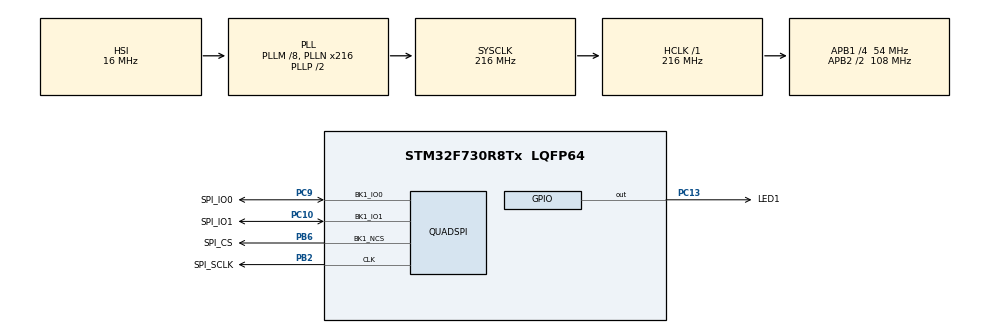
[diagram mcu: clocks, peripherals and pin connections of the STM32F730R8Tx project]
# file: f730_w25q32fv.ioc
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CORTEX_M7.ART_ACCLERATOR_ENABLE=0
CORTEX_M7.AccessPermission-Cortex_Memory_Protection_Unit_Region0_Settings=MPU_REGION_NO_ACCESS
CORTEX_M7.BaseAddress-Cortex_Memory_Protection_Unit_Region0_Settings=0x90000000
CORTEX_M7.CPU_DCache=Disabled
CORTEX_M7.CPU_ICache=Disabled
CORTEX_M7.DisableExec-Cortex_Memory_Protection_Unit_Region0_Settings=MPU_INSTRUCTION_ACCESS_ENABLE
CORTEX_M7.Enable-Cortex_Memory_Protection_Unit_Region0_Settings=MPU_REGION_ENABLE
CORTEX_M7.Enable-Cortex_Memory_Protection_Unit_Region10_Settings=__NULL
CORTEX_M7.Enable-Cortex_Memory_Protection_Unit_Region11_Settings=__NULL
CORTEX_M7.Enable-Cortex_Memory_Protection_Unit_Region12_Settings=__NULL
CORTEX_M7.Enable-Cortex_Memory_Protection_Unit_Region13_Settings=__NULL
CORTEX_M7.Enable-Cortex_Memory_Protection_Unit_Region14_Settings=__NULL
CORTEX_M7.Enable-Cortex_Memory_Protection_Unit_Region15_Settings=__NULL
CORTEX_M7.Enable-Cortex_Memory_Protection_Unit_Region1_Settings=__NULL
CORTEX_M7.Enable-Cortex_Memory_Protection_Unit_Region2_Settings=__NULL
CORTEX_M7.Enable-Cortex_Memory_Protection_Unit_Region3_Settings=__NULL
CORTEX_M7.Enable-Cortex_Memory_Protection_Unit_Region4_Settings=__NULL
CORTEX_M7.Enable-Cortex_Memory_Protection_Unit_Region5_Settings=__NULL
CORTEX_M7.Enable-Cortex_Memory_Protection_Unit_Region6_Settings=__NULL
CORTEX_M7.Enable-Cortex_Memory_Protection_Unit_Region7_Settings=__NULL
CORTEX_M7.Enable-Cortex_Memory_Protection_Unit_Region8_Settings=__NULL
CORTEX_M7.Enable-Cortex_Memory_Protection_Unit_Region9_Settings=__NULL
CORTEX_M7.FlashInterface=AXI_Enabled
CORTEX_M7.IsBufferable-Cortex_Memory_Protection_Unit_Region0_Settings=MPU_ACCESS_NOT_BUFFERABLE
CORTEX_M7.IsCacheable-Cortex_Memory_Protection_Unit_Region0_Settings=MPU_ACCESS_CACHEABLE
CORTEX_M7.IsShareable-Cortex_Memory_Protection_Unit_Region0_Settings=MPU_ACCESS_NOT_SHAREABLE
CORTEX_M7.MPU_Control=__NULL
CORTEX_M7.PREFETCH_ENABLE=0
CORTEX_M7.Size-Cortex_Memory_Protection_Unit_Region0_Settings=MPU_REGION_SIZE_4MB
CORTEX_M7.SubRegionDisable-Cortex_Memory_Protection_Unit_Region0_Settings=0x0
CORTEX_M7.TypeExtField-Cortex_Memory_Protection_Unit_Region0_Settings=MPU_TEX_LEVEL0
Mcu.Family=STM32F7
Mcu.Name=STM32F730R8Tx
Mcu.Package=LQFP64
NVIC.PriorityGroup=NVIC_PRIORITYGROUP_4
PA13.GPIO_Label=SWDIO
PA13.Mode=Serial_Wire
PA13.Signal=SYS_JTMS-SWDIO
PA14.GPIO_Label=SWCLK
PA14.Mode=Serial_Wire
PA14.Signal=SYS_JTCK-SWCLK
PB2.GPIO_Label=SPI_SCLK
PB2.Mode=Single Bank 1 2IOs
PB2.Signal=QUADSPI_CLK
PB6.GPIO_Label=SPI_CS
PB6.Mode=Single Bank 1 2IOs
PB6.Signal=QUADSPI_BK1_NCS
PC10.GPIO_Label=SPI_IO1
PC10.Mode=Single Bank 1 2IOs
PC10.Signal=QUADSPI_BK1_IO1
PC13.GPIO_Label=LED1
PC13.Signal=GPIO_Output
PC9.GPIO_Label=SPI_IO0
PC9.Mode=Single Bank 1 2IOs
PC9.Signal=QUADSPI_BK1_IO0
ProjectManager.HeapSize=0x200
ProjectManager.StackSize=0x400
ProjectManager.TargetToolchain=STM32CubeIDE
QUADSPI.ChipSelectHighTime=QSPI_CS_HIGH_TIME_1_CYCLE
QUADSPI.ClockMode=QSPI_CLOCK_MODE_0
QUADSPI.ClockPrescaler=2
QUADSPI.DualFlash=QSPI_DUALFLASH_DISABLE
QUADSPI.FifoThreshold=4
QUADSPI.FlashID=QSPI_FLASH_ID_1
QUADSPI.FlashSize=21
QUADSPI.SampleShifting=QSPI_SAMPLE_SHIFTING_NONE
RCC.AHBFreq_Value=216000000
RCC.APB1CLKDivider=RCC_HCLK_DIV4
RCC.APB1Freq_Value=54000000
RCC.APB1TimFreq_Value=108000000
RCC.APB2CLKDivider=RCC_HCLK_DIV2
RCC.APB2Freq_Value=108000000
RCC.APB2TimFreq_Value=216000000
RCC.CortexFreq_Value=216000000
RCC.HCLKFreq_Value=216000000
RCC.HSE_VALUE=8000000
RCC.HSI_VALUE=16000000
RCC.LSE_VALUE=32768
RCC.PLLM=8
RCC.PLLN=216
RCC.SYSCLKFreq_VALUE=216000000
RCC.SYSCLKSource=RCC_SYSCLKSOURCE_PLLCLK
RCC.USART1CLockSelection=RCC_USART1CLKSOURCE_SYSCLK
RCC.USBFreq_Value=216000000
RCC.VCOOutputFreq_Value=432000000
board=custom

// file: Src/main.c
/* USER CODE BEGIN Header */
/**
  ******************************************************************************
  * @file           : main.c
  * @brief          : Main program body
  ******************************************************************************
  * @attention
  *
  * <h2><center>&copy; Copyright (c) 2020 STMicroelectronics.
  * All rights reserved.</center></h2>
  *
  * This software component is licensed by ST under BSD 3-Clause license,
  * the "License"; You may not use this file except in compliance with the
  * License. You may obtain a copy of the License at:
  *                        opensource.org/licenses/BSD-3-Clause
  *
  ******************************************************************************
  */
/* USER CODE END Header */
#include "main.h"

/* USER CODE BEGIN Includes */
#include <errno.h>
#include <sys/unistd.h> // STDOUT_FILENO, STDERR_FILENO
#include <string.h>

/* USER CODE END Includes */

QSPI_HandleTypeDef hqspi;

void SystemClock_Config(void);
static void MX_GPIO_Init(void);
static void MX_QUADSPI_Init(void);

int main(void)
{

  /* MCU Configuration--------------------------------------------------------*/

  /* Reset of all peripherals, Initializes the Flash interface and the Systick. */
  HAL_Init();

  /* Configure the system clock */
  SystemClock_Config();

  /* USER CODE BEGIN SysInit */

  __HAL_RCC_QSPI_FORCE_RESET();  //completely reset peripheral
  __HAL_RCC_QSPI_RELEASE_RESET();

  /* USER CODE END SysInit */

  /* Initialize all configured peripherals */
  MX_GPIO_Init();
  MX_QUADSPI_Init();
  /* USER CODE BEGIN 2 */

  return 1;

  /* USER CODE END 2 */

  /* Infinite loop */
  while (1)
  {

  }
}

void SystemClock_Config(void)
{
  RCC_OscInitTypeDef RCC_OscInitStruct = {0};
  RCC_ClkInitTypeDef RCC_ClkInitStruct = {0};

  /** Configure the main internal regulator output voltage
  */
  __HAL_RCC_PWR_CLK_ENABLE();
  __HAL_PWR_VOLTAGESCALING_CONFIG(PWR_REGULATOR_VOLTAGE_SCALE1);
  /** Initializes the RCC Oscillators according to the specified parameters
  * in the RCC_OscInitTypeDef structure.
  */
  RCC_OscInitStruct.OscillatorType = RCC_OSCILLATORTYPE_HSI;
  RCC_OscInitStruct.HSIState = RCC_HSI_ON;
  RCC_OscInitStruct.HSICalibrationValue = RCC_HSICALIBRATION_DEFAULT;
  RCC_OscInitStruct.PLL.PLLState = RCC_PLL_ON;
  RCC_OscInitStruct.PLL.PLLSource = RCC_PLLSOURCE_HSI;
  RCC_OscInitStruct.PLL.PLLM = 8;
  RCC_OscInitStruct.PLL.PLLN = 216;
  RCC_OscInitStruct.PLL.PLLP = RCC_PLLP_DIV2;
  RCC_OscInitStruct.PLL.PLLQ = 2;
  if (HAL_RCC_OscConfig(&RCC_OscInitStruct) != HAL_OK)
  {
    Error_Handler();
  }
  /** Activate the Over-Drive mode
  */
  if (HAL_PWREx_EnableOverDrive() != HAL_OK)
  {
    Error_Handler();
  }
  /** Initializes the CPU, AHB and APB buses clocks
  */
  RCC_ClkInitStruct.ClockType = RCC_CLOCKTYPE_HCLK|RCC_CLOCKTYPE_SYSCLK
                              |RCC_CLOCKTYPE_PCLK1|RCC_CLOCKTYPE_PCLK2;
  RCC_ClkInitStruct.SYSCLKSource = RCC_SYSCLKSOURCE_PLLCLK;
  RCC_ClkInitStruct.AHBCLKDivider = RCC_SYSCLK_DIV1;
  RCC_ClkInitStruct.APB1CLKDivider = RCC_HCLK_DIV4;
  RCC_ClkInitStruct.APB2CLKDivider = RCC_HCLK_DIV2;

  if (HAL_RCC_ClockConfig(&RCC_ClkInitStruct, FLASH_LATENCY_7) != HAL_OK)
  {
    Error_Handler();
  }
}

static void MX_QUADSPI_Init(void)
{

  /* QUADSPI parameter configuration*/
  hqspi.Instance = QUADSPI;
  hqspi.Init.ClockPrescaler = 2;
  hqspi.Init.FifoThreshold = 4;
  hqspi.Init.SampleShifting = QSPI_SAMPLE_SHIFTING_NONE;
  hqspi.Init.FlashSize = 21;
  hqspi.Init.ChipSelectHighTime = QSPI_CS_HIGH_TIME_1_CYCLE;
  hqspi.Init.ClockMode = QSPI_CLOCK_MODE_0;
  hqspi.Init.FlashID = QSPI_FLASH_ID_1;
  hqspi.Init.DualFlash = QSPI_DUALFLASH_DISABLE;
  if (HAL_QSPI_Init(&hqspi) != HAL_OK)
  {
    Error_Handler();
  }

}

static void MX_GPIO_Init(void)
{
  GPIO_InitTypeDef GPIO_InitStruct = {0};

  /* GPIO Ports Clock Enable */
  __HAL_RCC_GPIOC_CLK_ENABLE();
  __HAL_RCC_GPIOB_CLK_ENABLE();
  __HAL_RCC_GPIOA_CLK_ENABLE();

  /*Configure GPIO pin Output Level */
  HAL_GPIO_WritePin(LED1_GPIO_Port, LED1_Pin, GPIO_PIN_RESET);

  /*Configure GPIO pin : LED1_Pin */
  GPIO_InitStruct.Pin = LED1_Pin;
  GPIO_InitStruct.Mode = GPIO_MODE_OUTPUT_PP;
  GPIO_InitStruct.Pull = GPIO_NOPULL;
  GPIO_InitStruct.Speed = GPIO_SPEED_FREQ_LOW;
  HAL_GPIO_Init(LED1_GPIO_Port, &GPIO_InitStruct);

}

void Error_Handler(void)
{
}

/************************ (C) COPYRIGHT STMicroelectronics *****END OF FILE****/
